# PIC18F05Q20 register map
Vendor: Microchip
Registers are 8-bit, read-write, reset 0x0 unless marked. A register's access mark holds for its fields unless they carry their own. Addresses are absolute, and some are shared; only a register's first bit layout is shown; [hi:lo] are bit positions; {n}, {i} and the like mark numbered series.

## DOS_xxxxx_port_control
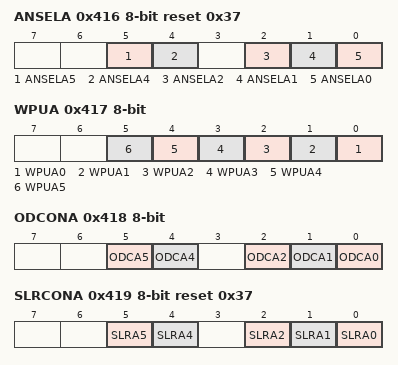
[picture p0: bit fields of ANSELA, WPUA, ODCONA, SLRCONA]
0x416 ANSELA reset 0x37
  [5] ANSELA5, [4] ANSELA4, [2] ANSELA2, [1] ANSELA1, [0] ANSELA0
0x417 WPUA
  [n] WPUA{n} (n=0..5)
0x418 ODCONA
  [5] ODCA5, [4] ODCA4, [2] ODCA2, [1] ODCA1, [0] ODCA0
0x419 SLRCONA reset 0x37
  [5] SLRA5, [4] SLRA4, [2] SLRA2, [1] SLRA1, [0] SLRA0
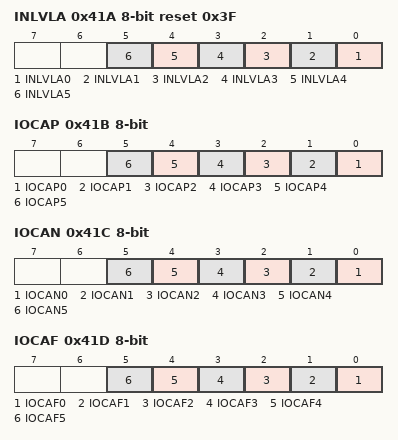
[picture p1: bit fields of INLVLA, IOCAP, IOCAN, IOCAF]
0x41A INLVLA reset 0x3F
  [n] INLVLA{n} (n=0..5)
0x41B IOCAP
  [n] IOCAP{n} (n=0..5)
0x41C IOCAN
  [n] IOCAN{n} (n=0..5)
0x41D IOCAF
  [n] IOCAF{n} (n=0..5)
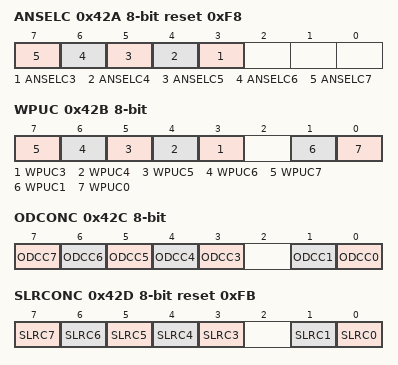
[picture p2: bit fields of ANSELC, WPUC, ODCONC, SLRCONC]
0x42A ANSELC reset 0xF8
  [n] ANSELC{n} (n=3..7)
0x42B WPUC
  [n] WPUC{n} (n=3..7), [1] WPUC1, [0] WPUC0
0x42C ODCONC
  [n] ODCC{n} (n=3..7), [1] ODCC1, [0] ODCC0
0x42D SLRCONC reset 0xFB
  [n] SLRC{n} (n=3..7), [1] SLRC1, [0] SLRC0
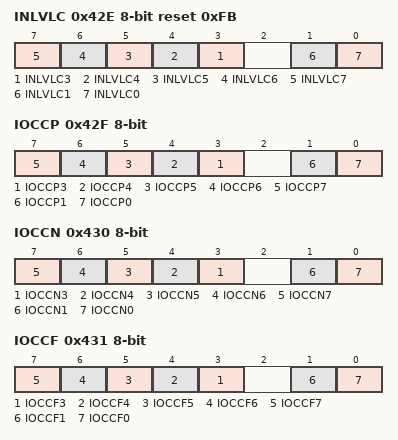
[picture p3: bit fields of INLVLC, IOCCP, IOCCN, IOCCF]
0x42E INLVLC reset 0xFB
  [n] INLVLC{n} (n=3..7), [1] INLVLC1, [0] INLVLC0
0x42F IOCCP
  [n] IOCCP{n} (n=3..7), [1] IOCCP1, [0] IOCCP0
0x430 IOCCN
  [n] IOCCN{n} (n=3..7), [1] IOCCN1, [0] IOCCN0
0x431 IOCCF
  [n] IOCCF{n} (n=3..7), [1] IOCCF1, [0] IOCCF0
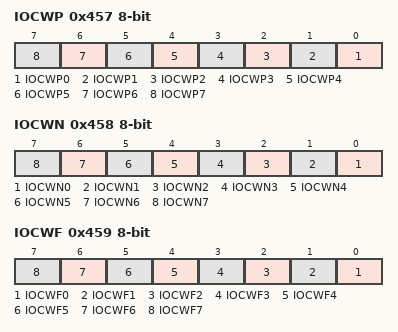
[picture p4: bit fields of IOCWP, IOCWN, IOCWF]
0x457 IOCWP
  [n] IOCWP{n} (n=0..7)
0x458 IOCWN
  [n] IOCWN{n} (n=0..7)
0x459 IOCWF
  [n] IOCWF{n} (n=0..7)

## int
0x460 IVTLOCK
  [0] IVTLOCKED
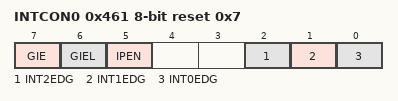
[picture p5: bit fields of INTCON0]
0x461 INTCON0 reset 0x7
  [7] GIE, [6] GIEL, [5] IPEN, [2] INT2EDG, [1] INT1EDG, [0] INT0EDG
0x462 INTCON1 ro
  [7:6] STAT
0x463 IVTADL
0x464 IVTADH
0x465 IVTADU
  [4:0] IVTADU
0x466 IVTBASEL
0x467 IVTBASEH
0x468 IVTBASEU
  [4:0] IVTBASEU

## DOS_xxxx_Interrupts
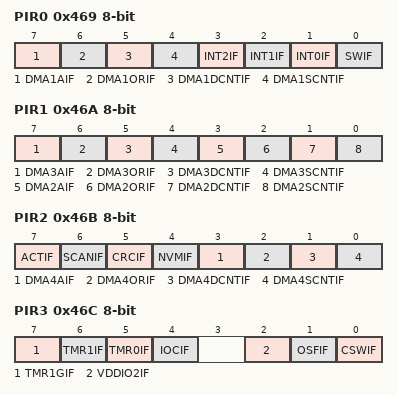
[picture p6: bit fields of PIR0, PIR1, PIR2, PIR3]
0x469 PIR0
  [7] DMA1AIF, [6] DMA1ORIF, [5] DMA1DCNTIF, [4] DMA1SCNTIF, [3] INT2IF, [2] INT1IF ro, [1] INT0IF, [0] SWIF
0x46A PIR1
  [7] DMA3AIF, [6] DMA3ORIF, [5] DMA3DCNTIF, [4] DMA3SCNTIF, [3] DMA2AIF, [2] DMA2ORIF, [1] DMA2DCNTIF, [0] DMA2SCNTIF
0x46B PIR2
  [7] ACTIF, [6] SCANIF, [5] CRCIF, [4] NVMIF, [3] DMA4AIF, [2] DMA4ORIF, [1] DMA4DCNTIF, [0] DMA4SCNTIF
0x46C PIR3
  [7] TMR1GIF, [6] TMR1IF, [5] TMR0IF, [4] IOCIF, [2] VDDIO2IF, [1] OSFIF, [0] CSWIF
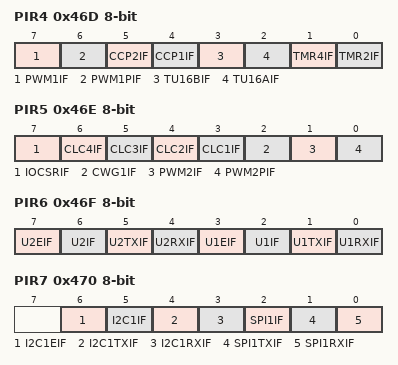
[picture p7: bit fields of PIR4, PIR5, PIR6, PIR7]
0x46D PIR4
  [7] PWM1IF, [6] PWM1PIF, [5] CCP2IF, [4] CCP1IF, [3] TU16BIF, [2] TU16AIF, [1] TMR4IF, [0] TMR2IF
0x46E PIR5 reset not defined — (power-on value x0000000)
  [7] IOCSRIF, [n+2] CLC{n}IF (n=1..4), [2] CWG1IF, [1] PWM2IF, [0] PWM2PIF
0x46F PIR6 ro
  [7] U2EIF, [6] U2IF, [5] U2TXIF, [4] U2RXIF, [3] U1EIF, [2] U1IF, [1] U1TXIF, [0] U1RXIF
0x470 PIR7 ro
  [6] I2C1EIF, [5] I2C1IF, [4] I2C1TXIF, [3] I2C1RXIF, [2] SPI1IF, [1] SPI1TXIF, [0] SPI1RXIF
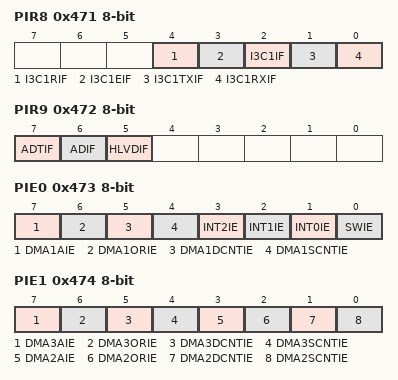
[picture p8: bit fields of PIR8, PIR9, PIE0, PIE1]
0x471 PIR8 ro
  [4] I3C1RIF, [3] I3C1EIF, [2] I3C1IF, [1] I3C1TXIF, [0] I3C1RXIF
0x472 PIR9
  [7] ADTIF, [6] ADIF, [5] HLVDIF
0x473 PIE0
  [7] DMA1AIE, [6] DMA1ORIE, [5] DMA1DCNTIE, [4] DMA1SCNTIE, [3] INT2IE, [2] INT1IE ro, [1] INT0IE, [0] SWIE
0x474 PIE1
  [7] DMA3AIE, [6] DMA3ORIE, [5] DMA3DCNTIE, [4] DMA3SCNTIE, [3] DMA2AIE, [2] DMA2ORIE, [1] DMA2DCNTIE, [0] DMA2SCNTIE
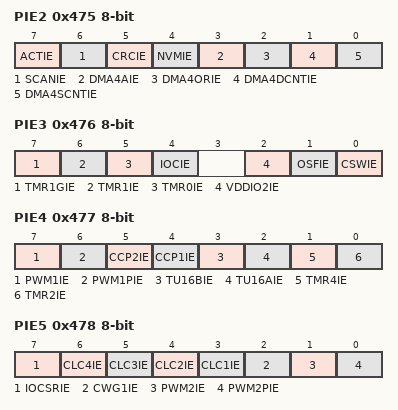
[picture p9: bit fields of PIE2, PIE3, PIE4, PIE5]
0x475 PIE2
  [7] ACTIE, [6] SCANIE, [5] CRCIE, [4] NVMIE, [3] DMA4AIE, [2] DMA4ORIE, [1] DMA4DCNTIE, [0] DMA4SCNTIE
0x476 PIE3
  [7] TMR1GIE, [6] TMR1IE, [5] TMR0IE, [4] IOCIE, [2] VDDIO2IE, [1] OSFIE, [0] CSWIE
0x477 PIE4
  [7] PWM1IE, [6] PWM1PIE, [5] CCP2IE, [4] CCP1IE, [3] TU16BIE, [2] TU16AIE, [1] TMR4IE, [0] TMR2IE
0x478 PIE5 reset not defined — (power-on value x0000000)
  [7] IOCSRIE, [n+2] CLC{n}IE (n=1..4), [2] CWG1IE, [1] PWM2IE, [0] PWM2PIE
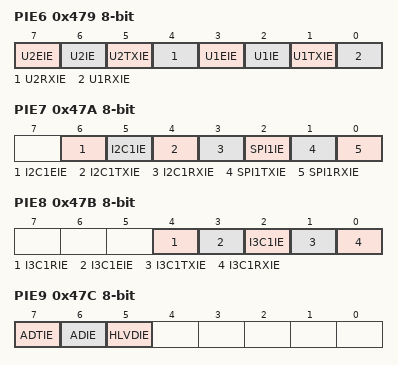
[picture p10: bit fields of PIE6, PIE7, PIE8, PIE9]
0x479 PIE6 ro
  [7] U2EIE, [6] U2IE, [5] U2TXIE, [4] U2RXIE, [3] U1EIE, [2] U1IE, [1] U1TXIE, [0] U1RXIE
0x47A PIE7 ro
  [6] I2C1EIE, [5] I2C1IE, [4] I2C1TXIE, [3] I2C1RXIE, [2] SPI1IE, [1] SPI1TXIE, [0] SPI1RXIE
0x47B PIE8 ro
  [4] I3C1RIE, [3] I3C1EIE, [2] I3C1IE, [1] I3C1TXIE, [0] I3C1RXIE
0x47C PIE9
  [7] ADTIE, [6] ADIE, [5] HLVDIE
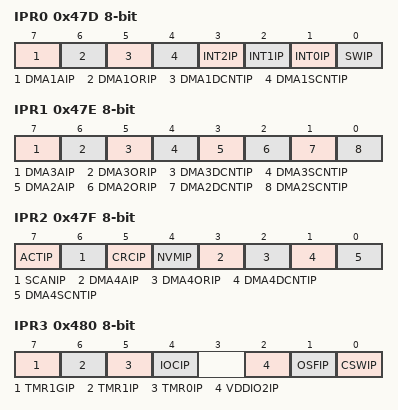
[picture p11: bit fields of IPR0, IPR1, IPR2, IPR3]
0x47D IPR0
  [7] DMA1AIP, [6] DMA1ORIP, [5] DMA1DCNTIP, [4] DMA1SCNTIP, [3] INT2IP, [2] INT1IP ro, [1] INT0IP, [0] SWIP
0x47E IPR1
  [7] DMA3AIP, [6] DMA3ORIP, [5] DMA3DCNTIP, [4] DMA3SCNTIP, [3] DMA2AIP, [2] DMA2ORIP, [1] DMA2DCNTIP, [0] DMA2SCNTIP
0x47F IPR2
  [7] ACTIP, [6] SCANIP, [5] CRCIP, [4] NVMIP, [3] DMA4AIP, [2] DMA4ORIP, [1] DMA4DCNTIP, [0] DMA4SCNTIP
0x480 IPR3
  [7] TMR1GIP, [6] TMR1IP, [5] TMR0IP, [4] IOCIP, [2] VDDIO2IP, [1] OSFIP, [0] CSWIP
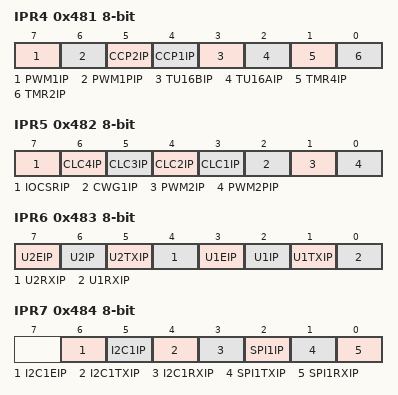
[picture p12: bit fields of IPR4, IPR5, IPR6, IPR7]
0x481 IPR4
  [7] PWM1IP, [6] PWM1PIP, [5] CCP2IP, [4] CCP1IP, [3] TU16BIP, [2] TU16AIP, [1] TMR4IP, [0] TMR2IP
0x482 IPR5 reset not defined — (power-on value x0000000)
  [7] IOCSRIP, [n+2] CLC{n}IP (n=1..4), [2] CWG1IP, [1] PWM2IP, [0] PWM2PIP
0x483 IPR6 ro
  [7] U2EIP, [6] U2IP, [5] U2TXIP, [4] U2RXIP, [3] U1EIP, [2] U1IP, [1] U1TXIP, [0] U1RXIP
0x484 IPR7 ro
  [6] I2C1EIP, [5] I2C1IP, [4] I2C1TXIP, [3] I2C1RXIP, [2] SPI1IP, [1] SPI1TXIP, [0] SPI1RXIP
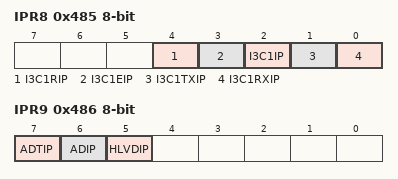
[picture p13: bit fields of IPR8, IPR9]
0x485 IPR8 ro
  [4] I3C1RIP, [3] I3C1EIP, [2] I3C1IP, [1] I3C1TXIP, [0] I3C1RXIP
0x486 IPR9
  [7] ADTIP, [6] ADIP, [5] HLVDIP

## DOS_PORTx
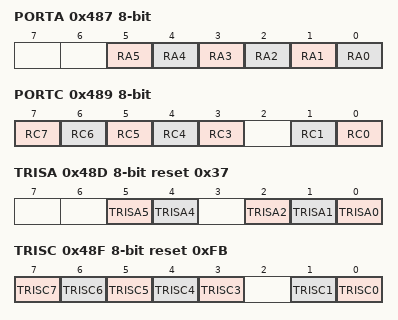
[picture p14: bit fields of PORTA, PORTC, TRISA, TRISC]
0x487 PORTA reset not defined — (power-on value --xxxxxx)
  [5] RA5, [4] RA4, [3] RA3 ro, [2] RA2, [1] RA1, [0] RA0
0x489 PORTC reset not defined — (power-on value xxxxx-xx)
  [n] RC{n} (n=3..7), [1] RC1, [0] RC0
0x48D TRISA reset 0x37
  [5] TRISA5, [4] TRISA4, [2] TRISA2, [1] TRISA1, [0] TRISA0
0x48F TRISC reset 0xFB
  [n] TRISC{n} (n=3..7), [1] TRISC1, [0] TRISC0
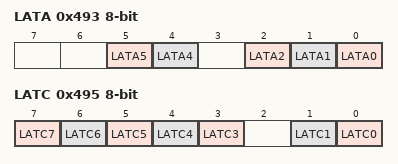
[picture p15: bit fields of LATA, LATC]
0x493 LATA reset not defined — (power-on value --xx-xxx)
  [5] LATA5, [4] LATA4, [2] LATA2, [1] LATA1, [0] LATA0
0x495 LATC reset not defined — (power-on value xxxxx-xx)
  [n] LATC{n} (n=3..7), [1] LATC1, [0] LATC0

## io_vport
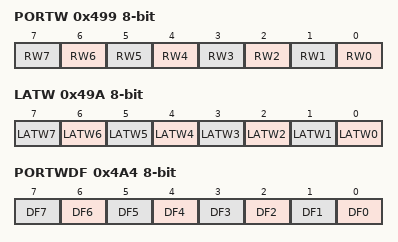
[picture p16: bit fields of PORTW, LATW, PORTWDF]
0x499 PORTW
  [n] RW{n} (n=0..7)
0x49A LATW
  [n] LATW{n} (n=0..7)
{0x49B+i} PORTWIN{i} (i=0..7)
  [2:0] IN
0x4A3 PORTWCLK — Virtual Port Control Register
  [4:0] CLK
0x4A4 PORTWDF
  [n] DF{n} (n=0..7)
0x4A5 PORTWCON
  [0] CLKEN

## DOS_0xxxx_io_multiv_ctrl_pic
0x4A6 MVIOSTAT ro reset not defined — MVIO STATUS REGISTER (power-on value -------u)
  [0] VDDIO2RDY
